# earlgrey register map
Vendor: lowRISC OpenTitan; File version: snapshot-20191101-1-518-g9293d546-dirty
CPU: RISCV 0, little endian, MPU, no FPU, 0 interrupt priority bits
Registers are 32-bit, read-write, reset 0x0 unless marked. A register's access mark holds for its fields unless they carry their own. Offsets are from the block's base; [hi:lo] are bit positions; <NAME> marks a mode.

## gpio
Base 0x40010000
0x00 INTR_STATE (reset mask 0x1) — Interrupt State Register
  [31:0] gpio write-1-clears — raised if any of GPIO pin detects configured interrupt mode
0x04 INTR_ENABLE (reset mask 0x1) — Interrupt Enable Register
  [31:0] gpio — Enable interrupt when corresponding bit in !!INTR_STATE.gpio is set
0x08 INTR_TEST wo (reset mask 0x1) — Interrupt Test Register
  [31:0] gpio — Write 1 to force corresponding bit in !!INTR_STATE.gpio to 1
0x0C DATA_IN ro reset not defined — GPIO Input data read value
0x10 DIRECT_OUT — GPIO direct output data write value
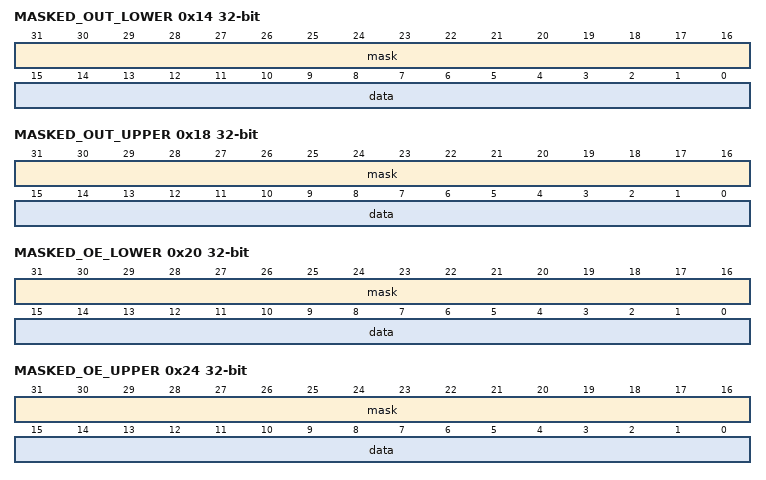
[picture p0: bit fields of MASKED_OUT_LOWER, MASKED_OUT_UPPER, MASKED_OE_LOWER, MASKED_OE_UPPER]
0x14 MASKED_OUT_LOWER (reset mask 0xFFFF) — GPIO write data lower with mask. Masked write for DATA_OUT[15:0]. Upper 16 bits of this register are used as mask. Writing lower 16 bits of the register changes DATA_OUT[15:0] value if mask bits are set. Read-back of this register returns upper 16 bits as zero and lower 16 bits as DATA_OUT[15:0].
  [31:16] mask wo — Write data mask[15:0]. A value of 1 in mask[i] allows the updating of DATA_OUT[i], 0 <= i <= 15
  [15:0] data — Write data value[15:0]. Value to write into DATA_OUT[i], valid in the presence of mask[i]==1
0x18 MASKED_OUT_UPPER (reset mask 0xFFFF) — GPIO write data upper with mask. Masked write for DATA_OUT[31:16]. Upper 16 bits of this register are used as mask. Writing lower 16 bits of the register changes DATA_OUT[31:16] value if mask bits are set. Read-back of this register returns upper 16 bits as zero and lower 16 bits as DATA_OUT[31:16].
  [31:16] mask wo — Write data mask[31:16]. A value of 1 in mask[i] allows the updating of DATA_OUT[i], 16 <= i <= 31
  [15:0] data — Write data value[31:16]. Value to write into DATA_OUT[i], valid in the presence of mask[i]==1
0x1C DIRECT_OE — GPIO Output Enable. Setting direct_oe[i] to 1 enables output mode for GPIO[i]
0x20 MASKED_OE_LOWER — GPIO write Output Enable lower with mask. Masked write for DATA_OE[15:0], the register that controls output mode for GPIO pins [15:0]. Upper 16 bits of this register are used as mask. Writing lower 16 bits of the register changes DATA_OE[15:0] value if mask bits are set. Read-back of this register returns upper 16 bits as zero and lower 16 bits as DATA_OE[15:0].
  [31:16] mask — Write OE mask[15:0]. A value of 1 in mask[i] allows the updating of DATA_OE[i], 0 <= i <= 15
  [15:0] data — Write OE value[15:0]. Value to write into DATA_OE[i], valid in the presence of mask[i]==1
0x24 MASKED_OE_UPPER — GPIO write Output Enable upper with mask. Masked write for DATA_OE[31:16], the register that controls output mode for GPIO pins [31:16]. Upper 16 bits of this register are used as mask. Writing lower 16 bits of the register changes DATA_OE[31:16] value if mask bits are set. Read-back of this register returns upper 16 bits as zero and lower 16 bits as DATA_OE[31:16].
  [31:16] mask — Write OE mask[31:16]. A value of 1 in mask[i] allows the updating of DATA_OE[i], 16 <= i <= 31
  [15:0] data — Write OE value[31:16]. Value to write into DATA_OE[i], valid in the presence of mask[i]==1
0x28 INTR_CTRL_EN_RISING — GPIO interrupt enable for GPIO, rising edge. If !!INTR_ENABLE[i] is true, a value of 1 on !!INTR_CTRL_EN_RISING[i] enables rising-edge interrupt detection on GPIO[i].
0x2C INTR_CTRL_EN_FALLING — GPIO interrupt enable for GPIO, falling edge. If !!INTR_ENABLE[i] is true, a value of 1 on !!INTR_CTRL_EN_FALLING[i] enables falling-edge interrupt detection on GPIO[i].
0x30 INTR_CTRL_EN_LVLHIGH — GPIO interrupt enable for GPIO, level high. If !!INTR_ENABLE[i] is true, a value of 1 on !!INTR_CTRL_EN_LVLHIGH[i] enables level high interrupt detection on GPIO[i].
0x34 INTR_CTRL_EN_LVLLOW — GPIO interrupt enable for GPIO, level low. If !!INTR_ENABLE[i] is true, a value of 1 on !!INTR_CTRL_EN_LVLLOW[i] enables level low interrupt detection on GPIO[i].
0x38 CTRL_EN_INPUT_FILTER — filter enable for GPIO input bits. If !!CTRL_EN_INPUT_FILTER[i] is true, a value of input bit [i] must be stable for 16 cycles before transitioning.
